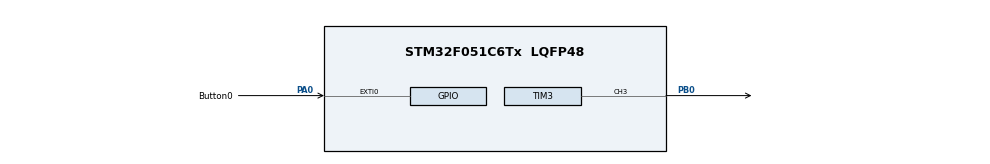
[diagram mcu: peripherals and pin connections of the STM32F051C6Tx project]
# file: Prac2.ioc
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Dma.Request0=TIM2_CH1
Dma.TIM2_CH1.0.Direction=DMA_MEMORY_TO_PERIPH
Dma.TIM2_CH1.0.Instance=DMA1_Channel5
Dma.TIM2_CH1.0.MemDataAlignment=DMA_MDATAALIGN_WORD
Dma.TIM2_CH1.0.MemInc=DMA_MINC_ENABLE
Dma.TIM2_CH1.0.Mode=DMA_CIRCULAR
Dma.TIM2_CH1.0.PeriphDataAlignment=DMA_PDATAALIGN_WORD
Dma.TIM2_CH1.0.PeriphInc=DMA_PINC_DISABLE
Dma.TIM2_CH1.0.Priority=DMA_PRIORITY_LOW
Mcu.Family=STM32F0
Mcu.Name=STM32F051C6Tx
Mcu.Package=LQFP48
NVIC.DMA1_Channel4_5_IRQn=true\:0\:0\:false\:false\:true\:false\:true\:true
PA0.GPIO_Label=Button0
PA0.GPIO_PuPd=GPIO_PULLUP
PA0.Signal=GPXTI0
PA13.Mode=Serial_Wire
PA13.Signal=SYS_SWDIO
PA14.Mode=Serial_Wire
PA14.Signal=SYS_SWCLK
PB0.Signal=S_TIM3_CH3
PF0-OSC_IN.Mode=HSE-External-Oscillator
PF0-OSC_IN.Signal=RCC_OSC_IN
PF1-OSC_OUT.Mode=HSE-External-Oscillator
PF1-OSC_OUT.Signal=RCC_OSC_OUT
ProjectManager.HeapSize=0x200
ProjectManager.StackSize=0x400
ProjectManager.TargetToolchain=STM32CubeIDE
SH.S_TIM3_CH3.0=TIM3_CH3,PWM Generation3 CH3
TIM2.AutoReloadPreload=TIM_AUTORELOAD_PRELOAD_ENABLE
TIM2.Channel-Output\ Compare1\ No\ Output=TIM_CHANNEL_1
TIM2.Period=100
TIM3.AutoReloadPreload=TIM_AUTORELOAD_PRELOAD_ENABLE
TIM3.Channel-PWM\ Generation3\ CH3=TIM_CHANNEL_3
TIM3.Period=1023
VP_TIM2_VS_ClockSourceINT.Mode=Internal
VP_TIM2_VS_no_output1.Mode=Output Compare1 No Output
VP_TIM3_VS_ClockSourceINT.Mode=Internal
board=custom

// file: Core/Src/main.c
/* USER CODE BEGIN Header */
/**
 ******************************************************************************
 * @file           : main.c
 * @brief          : Main program body
 ******************************************************************************
 * @attention
 *
 * Copyright (c) 2023 STMicroelectronics.
 * All rights reserved.
 *
 * This software is licensed under terms that can be found in the LICENSE file
 * in the root directory of this software component.
 * If no LICENSE file comes with this software, it is provided AS-IS.
 *
 ******************************************************************************
 */
/* USER CODE END Header */
#include "main.h"

/* USER CODE BEGIN Includes */
#include <stdio.h>
#include "stm32f0xx.h"
#include <lcd_stm32f0.h>
#include "lcd_stm32f0.c"

/* USER CODE END Includes */

/* USER CODE BEGIN PD */
// TODO: Add values for below variables
#define NS 128        // Number of samples in LUT
#define TIM2CLK 8e6   // STM Clock frequency
#define F_SIGNAL 50 // Frequency of output analog signal - I think based off our circuit?
/* USER CODE END PD */

TIM_HandleTypeDef htim2;
TIM_HandleTypeDef htim3;
DMA_HandleTypeDef hdma_tim2_ch1;

/* USER CODE BEGIN PV */
// TODO: Add code for global variables, including LUTs

//variables for tracking debouncing
uint32_t time_elapsed = 0;
uint32_t previous_time = 0;
uint32_t current_wave = 0;

//LUTs for the different waveforms
uint32_t Sin_LUT[NS] =
    {511, 536, 562, 587, 612, 636, 661, 685, 708, 731, 754, 776, 797, 818, 838, 857, 875, 892, 909, 924, 938,
     952, 964, 975, 985, 994, 1002, 1008, 1014, 1018, 1021, 1022, 1022, 1022, 1019, 1016, 1011, 1005, 998, 990,
     980, 970, 958, 945, 931, 916, 901, 884, 866, 847, 828, 808, 787, 765, 743, 720, 696, 673, 648, 624, 599,
     574, 549, 524, 498, 473, 448, 423, 398, 374, 349, 326, 302, 279, 257, 235, 214, 194, 175, 156, 138, 121,
     106, 91, 77, 64, 52, 42, 32, 24, 17, 11, 6, 3, 0, 0, 0, 1, 4, 8, 14, 20, 28, 37, 47, 58, 70, 84, 98, 113,
     130, 147, 165, 184, 204, 225, 246, 268, 291, 314, 337, 361, 386, 410, 435, 460, 486, 511};
uint32_t saw_LUT[NS] =
    {0, 8, 16, 24, 32, 40, 48, 56, 64, 72, 80, 88, 96, 104, 112, 120, 128, 136, 144, 153, 161, 169, 177, 185,
     193, 201, 209, 217, 225, 233, 241, 249, 257, 265, 273, 281, 289, 298, 306, 314, 322, 330, 338, 346, 354,
     362, 370, 378, 386, 394, 402, 410, 418, 426, 434, 443, 451, 459, 467, 475, 483, 491, 499, 507, 515, 523,
     531, 539, 547, 555, 563, 571, 579, 588, 596, 604, 612, 620, 628, 636, 644, 652, 660, 668, 676, 684, 692,
     700, 708, 716, 724, 733, 741, 749, 757, 765, 773, 781, 789, 797, 805, 813, 821, 829, 837, 845, 853, 861,
     869, 878, 886, 894, 902, 910, 918, 926, 934, 942, 950, 958, 966, 974, 982, 990, 998, 1006, 1014, 1023};
uint32_t triangle_LUT[NS] =
    {0, 16, 32, 48, 65, 81, 97, 113, 129, 145, 161, 177, 193, 209, 225, 241,
     257, 273, 289, 305, 321, 337, 353, 369, 385, 401, 417, 433, 449, 465, 481, 497,
     513, 529, 545, 561, 577, 593, 609, 625, 641, 657, 673, 689, 705, 721, 737, 753,
     769, 785, 801, 817, 833, 849, 865, 881, 897, 913, 929, 945, 961, 977, 993, 1009,
     1023, 1009, 993, 977, 961, 945, 929, 913, 897, 881, 865, 849, 833, 817, 801, 785,
     769, 753, 737, 721, 705, 689, 673, 657, 641, 625, 609, 593, 577, 561, 545, 529,
     513, 497, 481, 465, 449, 433, 417, 401, 385, 369, 353, 337, 321, 305, 289, 273,
     257, 241, 225, 209, 193, 177, 161, 145, 129, 113, 97, 81, 65, 48, 32, 16};

// TODO: Equation to calculate TIM2_Ticks

uint32_t TIM2_Ticks = TIM2CLK/(F_SIGNAL*NS); // How often to write new LUT value
uint32_t DestAddress = (uint32_t) & (TIM3->CCR3);  // Write LUT TO TIM3->CCR3 to modify PWM duty cycle

/* USER CODE END PV */

void SystemClock_Config(void);
static void MX_GPIO_Init(void);
static void MX_DMA_Init(void);
static void MX_TIM2_Init(void);
static void MX_TIM3_Init(void);
/* USER CODE BEGIN PFP */
void EXTI0_1_IRQHandler(void);
/* USER CODE END PFP */

int main(void)
{

  /* MCU Configuration--------------------------------------------------------*/

  /* Reset of all peripherals, Initializes the Flash interface and the Systick. */
  HAL_Init();

  /* USER CODE BEGIN Init */
  init_LCD();
  /* USER CODE END Init */

  /* Configure the system clock */
  SystemClock_Config();

  /* Initialize all configured peripherals */
  MX_GPIO_Init();
  MX_DMA_Init();
  MX_TIM2_Init();
  MX_TIM3_Init();
  /* USER CODE BEGIN 2 */
  char clockspeed = HAL_RCC_GetSysClockFreq(); // gets the current set clock speed of the chip
  printf(clockspeed);
  // TODO: Start TIM3 in PWM mode on channel 3
  HAL_TIM_PWM_Start(&htim3, TIM_CHANNEL_3);

  // TODO: Start TIM2 in Output Compare (OC) mode on channel 1.
  HAL_TIM_OC_Start(&htim2, TIM_CHANNEL_1);

  // TODO: Start DMA in IT mode on TIM2->CH1; Source is LUT and Dest is TIM3->CCR3; start with Sine LUT
  HAL_DMA_Start_IT(&hdma_tim2_ch1, (uint32_t)Sin_LUT, DestAddress, NS);
  // feeds the LUT values into the PWM generator tim3 based on tim2 timing

  delay(3000);

  // TODO: Write current waveform to LCD ("Sine")

  lcd_command(CLEAR);
  lcd_putstring("Sine");

  // TODO: Enable DMA (start transfer from LUT to CCR)
  __HAL_TIM_ENABLE_DMA(&htim2, TIM_DMA_CC1);

  /* USER CODE END 2 */

  /* Infinite loop */
  while (1)
  {

  }
}

void SystemClock_Config(void)
{
  LL_FLASH_SetLatency(LL_FLASH_LATENCY_0);
  while (LL_FLASH_GetLatency() != LL_FLASH_LATENCY_0)
  {
  }
  LL_RCC_HSI_Enable();

  /* Wait till HSI is ready */
  while (LL_RCC_HSI_IsReady() != 1)
  {
  }
  LL_RCC_HSI_SetCalibTrimming(16);
  LL_RCC_SetAHBPrescaler(LL_RCC_SYSCLK_DIV_1);
  LL_RCC_SetAPB1Prescaler(LL_RCC_APB1_DIV_1);
  LL_RCC_SetSysClkSource(LL_RCC_SYS_CLKSOURCE_HSI);

  /* Wait till System clock is ready */
  while (LL_RCC_GetSysClkSource() != LL_RCC_SYS_CLKSOURCE_STATUS_HSI)
  {
  }
  LL_SetSystemCoreClock(8000000);

  /* Update the time base */
  if (HAL_InitTick(TICK_INT_PRIORITY) != HAL_OK)
  {
    Error_Handler();
  }
}

static void MX_TIM2_Init(void)
{

  TIM_ClockConfigTypeDef sClockSourceConfig = {0};
  TIM_MasterConfigTypeDef sMasterConfig = {0};
  TIM_OC_InitTypeDef sConfigOC = {0};

  htim2.Instance = TIM2;
  htim2.Init.Prescaler = 0;
  htim2.Init.CounterMode = TIM_COUNTERMODE_UP;
  //Change period to time between LUT values
  htim2.Init.Period = TIM2_Ticks-1;
  htim2.Init.ClockDivision = TIM_CLOCKDIVISION_DIV1;
  htim2.Init.AutoReloadPreload = TIM_AUTORELOAD_PRELOAD_ENABLE;
  if (HAL_TIM_Base_Init(&htim2) != HAL_OK)
  {
    Error_Handler();
  }
  sClockSourceConfig.ClockSource = TIM_CLOCKSOURCE_INTERNAL;
  if (HAL_TIM_ConfigClockSource(&htim2, &sClockSourceConfig) != HAL_OK)
  {
    Error_Handler();
  }
  if (HAL_TIM_OC_Init(&htim2) != HAL_OK)
  {
    Error_Handler();
  }
  sMasterConfig.MasterOutputTrigger = TIM_TRGO_RESET;
  sMasterConfig.MasterSlaveMode = TIM_MASTERSLAVEMODE_DISABLE;
  if (HAL_TIMEx_MasterConfigSynchronization(&htim2, &sMasterConfig) != HAL_OK)
  {
    Error_Handler();
  }
  sConfigOC.OCMode = TIM_OCMODE_TIMING;
  sConfigOC.Pulse = 0;
  sConfigOC.OCPolarity = TIM_OCPOLARITY_HIGH;
  sConfigOC.OCFastMode = TIM_OCFAST_DISABLE;
  if (HAL_TIM_OC_ConfigChannel(&htim2, &sConfigOC, TIM_CHANNEL_1) != HAL_OK)
  {
    Error_Handler();
  }
}

static void MX_TIM3_Init(void)
{

  TIM_ClockConfigTypeDef sClockSourceConfig = {0};
  TIM_MasterConfigTypeDef sMasterConfig = {0};
  TIM_OC_InitTypeDef sConfigOC = {0};

  htim3.Instance = TIM3;
  htim3.Init.Prescaler = 0;
  htim3.Init.CounterMode = TIM_COUNTERMODE_UP;
  htim3.Init.Period = 1023;
  htim3.Init.ClockDivision = TIM_CLOCKDIVISION_DIV1;
  htim3.Init.AutoReloadPreload = TIM_AUTORELOAD_PRELOAD_ENABLE;
  if (HAL_TIM_Base_Init(&htim3) != HAL_OK)
  {
    Error_Handler();
  }
  sClockSourceConfig.ClockSource = TIM_CLOCKSOURCE_INTERNAL;
  if (HAL_TIM_ConfigClockSource(&htim3, &sClockSourceConfig) != HAL_OK)
  {
    Error_Handler();
  }
  if (HAL_TIM_PWM_Init(&htim3) != HAL_OK)
  {
    Error_Handler();
  }
  sMasterConfig.MasterOutputTrigger = TIM_TRGO_RESET;
  sMasterConfig.MasterSlaveMode = TIM_MASTERSLAVEMODE_DISABLE;
  if (HAL_TIMEx_MasterConfigSynchronization(&htim3, &sMasterConfig) != HAL_OK)
  {
    Error_Handler();
  }
  sConfigOC.OCMode = TIM_OCMODE_PWM1;
  sConfigOC.Pulse = 0;
  sConfigOC.OCPolarity = TIM_OCPOLARITY_HIGH;
  sConfigOC.OCFastMode = TIM_OCFAST_DISABLE;
  if (HAL_TIM_PWM_ConfigChannel(&htim3, &sConfigOC, TIM_CHANNEL_3) != HAL_OK)
  {
    Error_Handler();
  }
  HAL_TIM_MspPostInit(&htim3);
}

static void MX_DMA_Init(void)
{

  /* DMA controller clock enable */
  __HAL_RCC_DMA1_CLK_ENABLE();

  /* DMA interrupt init */
  /* DMA1_Channel4_5_IRQn interrupt configuration */
  HAL_NVIC_SetPriority(DMA1_Channel4_5_IRQn, 0, 0);
  HAL_NVIC_EnableIRQ(DMA1_Channel4_5_IRQn);
}

static void MX_GPIO_Init(void)
{
  LL_EXTI_InitTypeDef EXTI_InitStruct = {0};

  /* GPIO Ports Clock Enable */
  LL_AHB1_GRP1_EnableClock(LL_AHB1_GRP1_PERIPH_GPIOF);
  LL_AHB1_GRP1_EnableClock(LL_AHB1_GRP1_PERIPH_GPIOA);
  LL_AHB1_GRP1_EnableClock(LL_AHB1_GRP1_PERIPH_GPIOB);

  //
  LL_SYSCFG_SetEXTISource(LL_SYSCFG_EXTI_PORTA, LL_SYSCFG_EXTI_LINE0);

  //
  LL_GPIO_SetPinPull(Button0_GPIO_Port, Button0_Pin, LL_GPIO_PULL_UP);

  //
  LL_GPIO_SetPinMode(Button0_GPIO_Port, Button0_Pin, LL_GPIO_MODE_INPUT);

  //
  EXTI_InitStruct.Line_0_31 = LL_EXTI_LINE_0;
  EXTI_InitStruct.LineCommand = ENABLE;
  EXTI_InitStruct.Mode = LL_EXTI_MODE_IT;
  EXTI_InitStruct.Trigger = LL_EXTI_TRIGGER_RISING;
  LL_EXTI_Init(&EXTI_InitStruct);

  /* USER CODE BEGIN MX_GPIO_Init_2 */
  HAL_NVIC_SetPriority(EXTI0_1_IRQn, 0, 0);
  HAL_NVIC_EnableIRQ(EXTI0_1_IRQn);
  /* USER CODE END MX_GPIO_Init_2 */
}

/* USER CODE BEGIN 4 */
void EXTI0_1_IRQHandler(void)
{

  // TODO: Debounce using HAL_GetTick()
  time_elapsed = HAL_GetTick();
  if (time_elapsed - previous_time > 500)
  {
    // TODO: Disable DMA transfer and abort IT, then start DMA in IT mode with new LUT and re-enable transfer
    // HINT: Consider using C's "switch" function to handle LUT changes
    __HAL_TIM_DISABLE_DMA(&htim2, TIM_DMA_CC1);
    HAL_DMA_Abort_IT(&hdma_tim2_ch1);
    lcd_command(CLEAR);
    if (current_wave == 2)
      current_wave = 0;
    else
      current_wave++;
    switch (current_wave)
    {

    case 0:

      lcd_putstring("Sine");
      //start sine wave
      HAL_DMA_Start_IT(&hdma_tim2_ch1, (uint32_t) Sin_LUT, DestAddress, NS);

      break;
    case 1:

      lcd_putstring("Sawtooth");
      //start sawtooth wave
      HAL_DMA_Start_IT(&hdma_tim2_ch1, (uint32_t) saw_LUT, DestAddress, NS);
      break;
    case 2:

      lcd_putstring("Triangle");
      //start triangle wave
      HAL_DMA_Start_IT(&hdma_tim2_ch1, (uint32_t) triangle_LUT, DestAddress, NS);
      break;
    default:
      lcd_putstring("An error has occured with the wave counter");
      break;
    }

    // Enable DMA (start transfer from LUT to CCR)
    __HAL_TIM_ENABLE_DMA(&htim2, TIM_DMA_CC1);
    //update previous time to handle debounce
    previous_time = time_elapsed;

  }

  HAL_GPIO_EXTI_IRQHandler(Button0_Pin); // Clear interrupt flags
}
/* USER CODE END 4 */

void Error_Handler(void)
{
  __disable_irq();
  while (1)
  {
  }
}
